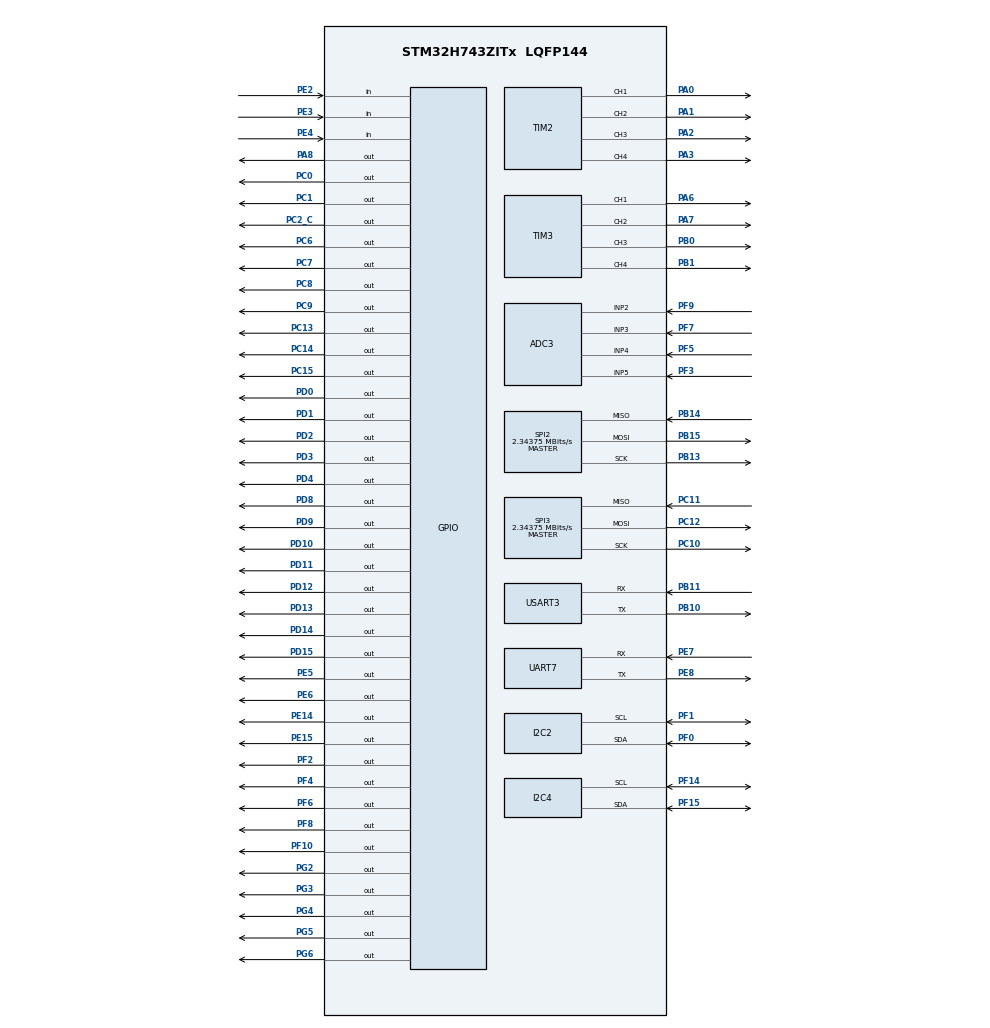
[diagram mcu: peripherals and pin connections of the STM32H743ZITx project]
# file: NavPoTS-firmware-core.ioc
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ADC3.Channel-0\#ChannelRegularConversion=ADC_CHANNEL_5
ADC3.NbrOfConversionFlag=1
ADC3.OffsetNumber-0\#ChannelRegularConversion=ADC_OFFSET_NONE
ADC3.OffsetSignedSaturation-0\#ChannelRegularConversion=DISABLE
ADC3.Rank-0\#ChannelRegularConversion=1
ADC3.SamplingTime-0\#ChannelRegularConversion=ADC_SAMPLETIME_1CYCLE_5
CORTEX_M7.default_mode_Activation=1
I2C2.Timing=0x307076AD
I2C4.Timing=0x307076AD
Mcu.Family=STM32H7
Mcu.Name=STM32H743ZITx
Mcu.Package=LQFP144
NVIC.PriorityGroup=NVIC_PRIORITYGROUP_4
PA0.Signal=S_TIM2_CH1_ETR
PA1.Signal=S_TIM2_CH2
PA11.Signal=USB_OTG_FS_DM
PA12.Signal=USB_OTG_FS_DP
PA13\ (JTMS/SWDIO).Signal=DEBUG_JTMS-SWDIO
PA14\ (JTCK/SWCLK).Signal=DEBUG_JTCK-SWCLK
PA2.Signal=S_TIM2_CH3
PA3.Signal=S_TIM2_CH4
PA6.Signal=S_TIM3_CH1
PA7.Signal=S_TIM3_CH2
PA8.Signal=GPIO_Output
PA9.Signal=USB_OTG_FS_VBUS
PB0.Signal=S_TIM3_CH3
PB1.Signal=S_TIM3_CH4
PB10.Mode=Asynchronous
PB10.Signal=USART3_TX
PB11.Mode=Asynchronous
PB11.Signal=USART3_RX
PB13.Mode=Full_Duplex_Master
PB13.Signal=SPI2_SCK
PB14.Mode=Full_Duplex_Master
PB14.Signal=SPI2_MISO
PB15.Mode=Full_Duplex_Master
PB15.Signal=SPI2_MOSI
PB3\ (JTDO/TRACESWO).Signal=DEBUG_JTDO-SWO
PC0.Signal=GPIO_Output
PC1.Signal=GPIO_Output
PC10.Mode=Full_Duplex_Master
PC10.Signal=SPI3_SCK
PC11.Mode=Full_Duplex_Master
PC11.Signal=SPI3_MISO
PC12.Mode=Full_Duplex_Master
PC12.Signal=SPI3_MOSI
PC13.Signal=GPIO_Output
PC14-OSC32_IN\ (OSC32_IN).Signal=GPIO_Output
PC15-OSC32_OUT\ (OSC32_OUT).Signal=GPIO_Output
PC2_C.Signal=GPIO_Output
PC6.Signal=GPIO_Output
PC7.Signal=GPIO_Output
PC8.Signal=GPIO_Output
PC9.Signal=GPIO_Output
PD0.Signal=GPIO_Output
PD1.Signal=GPIO_Output
PD10.Signal=GPIO_Output
PD11.Signal=GPIO_Output
PD12.Signal=GPIO_Output
PD13.Signal=GPIO_Output
PD14.Signal=GPIO_Output
PD15.Signal=GPIO_Output
PD2.Signal=GPIO_Output
PD3.Signal=GPIO_Output
PD4.Signal=GPIO_Output
PD8.Signal=GPIO_Output
PD9.Signal=GPIO_Output
PE14.Signal=GPIO_Output
PE15.Signal=GPIO_Output
PE2.Signal=GPIO_Input
PE3.Signal=GPIO_Input
PE4.Signal=GPIO_Input
PE5.Signal=GPIO_Output
PE6.Signal=GPIO_Output
PE7.Mode=Asynchronous
PE7.Signal=UART7_RX
PE8.Mode=Asynchronous
PE8.Signal=UART7_TX
PF0.Mode=I2C
PF0.Signal=I2C2_SDA
PF1.Mode=I2C
PF1.Signal=I2C2_SCL
PF10.Signal=GPIO_Output
PF14.Mode=I2C
PF14.Signal=I2C4_SCL
PF15.Mode=I2C
PF15.Signal=I2C4_SDA
PF2.Signal=GPIO_Output
PF3.Mode=IN5-Single-Ended
PF3.Signal=ADC3_INP5
PF4.Signal=GPIO_Output
PF5.Mode=IN4-Single-Ended
PF5.Signal=ADC3_INP4
PF6.Signal=GPIO_Output
PF7.Mode=IN3-Single-Ended
PF7.Signal=ADC3_INP3
PF8.Signal=GPIO_Output
PF9.Mode=IN2-Single-Ended
PF9.Signal=ADC3_INP2
PG2.Signal=GPIO_Output
PG3.Signal=GPIO_Output
PG4.Signal=GPIO_Output
PG5.Signal=GPIO_Output
PG6.Signal=GPIO_Output
PH0-OSC_IN\ (PH0).Mode=HSE-External-Clock-Source
PH0-OSC_IN\ (PH0).Signal=RCC_OSC_IN
ProjectManager.HeapSize=0x200
ProjectManager.StackSize=0x400
ProjectManager.TargetToolchain=STM32CubeIDE
RCC.ADCFreq_Value=75000000
RCC.APB1Freq_Value=118750000
RCC.APB2Freq_Value=118750000
RCC.APB3Freq_Value=118750000
RCC.APB4Freq_Value=118750000
RCC.CortexFreq_Value=475000000
RCC.D1PPRE=RCC_APB3_DIV2
RCC.D2PPRE1=RCC_APB1_DIV2
RCC.D2PPRE2=RCC_APB2_DIV2
RCC.D3PPRE=RCC_APB4_DIV2
RCC.DIVM1=2
RCC.DIVM2=2
RCC.DIVN1=76
RCC.DIVN2=12
RCC.EnbaleCSS=true
RCC.HCLKFreq_Value=237500000
RCC.HPRE=RCC_HCLK_DIV2
RCC.PLL2FRACN=0
RCC.PLLFRACN=0
RCC.PLLSourceVirtual=RCC_PLLSOURCE_HSE
RCC.SPI123CLockSelection=RCC_SPI123CLKSOURCE_PLL2
RCC.SYSCLKFreq_VALUE=475000000
RCC.SYSCLKSource=RCC_SYSCLKSOURCE_PLLCLK
RCC.USBFreq_Value=475000000
SH.S_TIM2_CH1_ETR.0=TIM2_CH1,PWM Generation1 CH1
SH.S_TIM2_CH2.0=TIM2_CH2,PWM Generation2 CH2
SH.S_TIM2_CH3.0=TIM2_CH3,PWM Generation3 CH3
SH.S_TIM2_CH4.0=TIM2_CH4,Output Compare4 CH4
SH.S_TIM3_CH1.0=TIM3_CH1,PWM Generation1 CH1
SH.S_TIM3_CH2.0=TIM3_CH2,PWM Generation2 CH2
SH.S_TIM3_CH3.0=TIM3_CH3,PWM Generation3 CH3
SH.S_TIM3_CH4.0=TIM3_CH4,PWM Generation4 CH4
SPI2.BaudRatePrescaler=SPI_BAUDRATEPRESCALER_32
SPI2.CalculateBaudRate=2.34375 MBits/s
SPI2.DataSize=SPI_DATASIZE_8BIT
SPI2.Direction=SPI_DIRECTION_2LINES
SPI2.Mode=SPI_MODE_MASTER
SPI2.VirtualType=VM_MASTER
SPI3.BaudRatePrescaler=SPI_BAUDRATEPRESCALER_32
SPI3.CalculateBaudRate=2.34375 MBits/s
SPI3.DataSize=SPI_DATASIZE_8BIT
SPI3.Direction=SPI_DIRECTION_2LINES
SPI3.Mode=SPI_MODE_MASTER
SPI3.VirtualType=VM_MASTER
TIM2.Channel-Output\ Compare4\ CH4=TIM_CHANNEL_4
TIM2.Channel-PWM\ Generation1\ CH1=TIM_CHANNEL_1
TIM2.Channel-PWM\ Generation2\ CH2=TIM_CHANNEL_2
TIM2.Channel-PWM\ Generation3\ CH3=TIM_CHANNEL_3
TIM3.Channel-PWM\ Generation1\ CH1=TIM_CHANNEL_1
TIM3.Channel-PWM\ Generation2\ CH2=TIM_CHANNEL_2
TIM3.Channel-PWM\ Generation3\ CH3=TIM_CHANNEL_3
TIM3.Channel-PWM\ Generation4\ CH4=TIM_CHANNEL_4
USART3.VirtualMode-Asynchronous=VM_ASYNC
VP_MEMORYMAP_VS_MEMORYMAP.Mode=CurAppReg
board=custom

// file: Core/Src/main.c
/* USER CODE BEGIN Header */
/**
  ******************************************************************************
  * @file           : main.c
  * @brief          : Main program body
  ******************************************************************************
  * @attention
  *
  * Copyright (c) 2026 STMicroelectronics.
  * All rights reserved.
  *
  * This software is licensed under terms that can be found in the LICENSE file
  * in the root directory of this software component.
  * If no LICENSE file comes with this software, it is provided AS-IS.
  *
  ******************************************************************************
  */
/* USER CODE END Header */
#include "main.h"
#include "adc.h"
#include "i2c.h"
#include "spi.h"
#include "tim.h"
#include "usart.h"
#include "gpio.h"

/* USER CODE BEGIN Includes */
#include <stdio.h>
#include "ASM330LHHXTR.h"
#include "H3LIS331DL.h"
#include "MMC5983MA.h"
/* USER CODE END Includes */

void SystemClock_Config(void);
void PeriphCommonClock_Config(void);
static void MPU_Config(void);

int main(void)
{

  /* MPU Configuration--------------------------------------------------------*/
  MPU_Config();

  /* MCU Configuration--------------------------------------------------------*/

  /* Reset of all peripherals, Initializes the Flash interface and the Systick. */
  HAL_Init();

  /* Configure the system clock */
  SystemClock_Config();

  /* Configure the peripherals common clocks */
  PeriphCommonClock_Config();

  /* Initialize all configured peripherals */
  MX_GPIO_Init();
  MX_SPI3_Init();
  MX_SPI2_Init();
  MX_UART7_Init();
  MX_USART3_UART_Init();
  MX_ADC3_Init();
  MX_I2C2_Init();
  MX_I2C4_Init();
  MX_TIM2_Init();
  MX_TIM3_Init();
  /* USER CODE BEGIN 2 */
  ASM330LHHXTR_Data data;

  ASM330LHHXTR_Verify();
  ASM330LHHXTR_Init();
  H3LIS331DL_Verify();
  MMC5983MA_Verify();

  /* USER CODE END 2 */

  /* Infinite loop */
  while (1)
  {

    /* USER CODE BEGIN 3 */
	ASM330LHHXTR_ReadData(&data);
	printf("temp %f, gx %f, gy %f, gz %f, ax %f, ay %f, az %f\r\n", data.temp, data.gx, data.gy, data.gz, data.ax, data.ay, data.az);
	HAL_Delay(150);
  }
  /* USER CODE END 3 */
}

void SystemClock_Config(void)
{
  RCC_OscInitTypeDef RCC_OscInitStruct = {0};
  RCC_ClkInitTypeDef RCC_ClkInitStruct = {0};

  /** Supply configuration update enable
  */
  HAL_PWREx_ConfigSupply(PWR_LDO_SUPPLY);

  /** Configure the main internal regulator output voltage
  */
  __HAL_PWR_VOLTAGESCALING_CONFIG(PWR_REGULATOR_VOLTAGE_SCALE0);

  while(!__HAL_PWR_GET_FLAG(PWR_FLAG_VOSRDY)) {}

  /** Initializes the RCC Oscillators according to the specified parameters
  * in the RCC_OscInitTypeDef structure.
  */
  RCC_OscInitStruct.OscillatorType = RCC_OSCILLATORTYPE_HSE;
  RCC_OscInitStruct.HSEState = RCC_HSE_BYPASS;
  RCC_OscInitStruct.PLL.PLLState = RCC_PLL_ON;
  RCC_OscInitStruct.PLL.PLLSource = RCC_PLLSOURCE_HSE;
  RCC_OscInitStruct.PLL.PLLM = 2;
  RCC_OscInitStruct.PLL.PLLN = 76;
  RCC_OscInitStruct.PLL.PLLP = 2;
  RCC_OscInitStruct.PLL.PLLQ = 2;
  RCC_OscInitStruct.PLL.PLLR = 2;
  RCC_OscInitStruct.PLL.PLLRGE = RCC_PLL1VCIRANGE_3;
  RCC_OscInitStruct.PLL.PLLVCOSEL = RCC_PLL1VCOWIDE;
  RCC_OscInitStruct.PLL.PLLFRACN = 0;
  if (HAL_RCC_OscConfig(&RCC_OscInitStruct) != HAL_OK)
  {
    Error_Handler();
  }

  /** Initializes the CPU, AHB and APB buses clocks
  */
  RCC_ClkInitStruct.ClockType = RCC_CLOCKTYPE_HCLK|RCC_CLOCKTYPE_SYSCLK
                              |RCC_CLOCKTYPE_PCLK1|RCC_CLOCKTYPE_PCLK2
                              |RCC_CLOCKTYPE_D3PCLK1|RCC_CLOCKTYPE_D1PCLK1;
  RCC_ClkInitStruct.SYSCLKSource = RCC_SYSCLKSOURCE_PLLCLK;
  RCC_ClkInitStruct.SYSCLKDivider = RCC_SYSCLK_DIV1;
  RCC_ClkInitStruct.AHBCLKDivider = RCC_HCLK_DIV2;
  RCC_ClkInitStruct.APB3CLKDivider = RCC_APB3_DIV2;
  RCC_ClkInitStruct.APB1CLKDivider = RCC_APB1_DIV2;
  RCC_ClkInitStruct.APB2CLKDivider = RCC_APB2_DIV2;
  RCC_ClkInitStruct.APB4CLKDivider = RCC_APB4_DIV2;

  if (HAL_RCC_ClockConfig(&RCC_ClkInitStruct, FLASH_LATENCY_4) != HAL_OK)
  {
    Error_Handler();
  }

  /** Enables the Clock Security System
  */
  HAL_RCC_EnableCSS();
}

void PeriphCommonClock_Config(void)
{
  RCC_PeriphCLKInitTypeDef PeriphClkInitStruct = {0};

  /** Initializes the peripherals clock
  */
  PeriphClkInitStruct.PeriphClockSelection = RCC_PERIPHCLK_ADC|RCC_PERIPHCLK_SPI3
                              |RCC_PERIPHCLK_SPI2;
  PeriphClkInitStruct.PLL2.PLL2M = 2;
  PeriphClkInitStruct.PLL2.PLL2N = 12;
  PeriphClkInitStruct.PLL2.PLL2P = 2;
  PeriphClkInitStruct.PLL2.PLL2Q = 2;
  PeriphClkInitStruct.PLL2.PLL2R = 2;
  PeriphClkInitStruct.PLL2.PLL2RGE = RCC_PLL2VCIRANGE_3;
  PeriphClkInitStruct.PLL2.PLL2VCOSEL = RCC_PLL2VCOMEDIUM;
  PeriphClkInitStruct.PLL2.PLL2FRACN = 0;
  PeriphClkInitStruct.Spi123ClockSelection = RCC_SPI123CLKSOURCE_PLL2;
  PeriphClkInitStruct.AdcClockSelection = RCC_ADCCLKSOURCE_PLL2;
  if (HAL_RCCEx_PeriphCLKConfig(&PeriphClkInitStruct) != HAL_OK)
  {
    Error_Handler();
  }
}

/* USER CODE BEGIN 4 */
void HAL_RCC_CSSCallback(void)
{
	//printf("CSS Callback Triggered!");
	HAL_GPIO_WritePin(GPIOE, GPIO_PIN_14, GPIO_PIN_SET);
	while(1)
	{

	}
}

int _write(int file, char *ptr, int len)
{
  HAL_UART_Transmit(&huart7, (uint8_t *)ptr, len, HAL_MAX_DELAY);
  return len;
}
/* USER CODE END 4 */

 /* MPU Configuration */

void MPU_Config(void)
{
  MPU_Region_InitTypeDef MPU_InitStruct = {0};

  /* Disables the MPU */
  HAL_MPU_Disable();

  /** Initializes and configures the Region and the memory to be protected
  */
  MPU_InitStruct.Enable = MPU_REGION_ENABLE;
  MPU_InitStruct.Number = MPU_REGION_NUMBER0;
  MPU_InitStruct.BaseAddress = 0x0;
  MPU_InitStruct.Size = MPU_REGION_SIZE_4GB;
  MPU_InitStruct.SubRegionDisable = 0x87;
  MPU_InitStruct.TypeExtField = MPU_TEX_LEVEL0;
  MPU_InitStruct.AccessPermission = MPU_REGION_NO_ACCESS;
  MPU_InitStruct.DisableExec = MPU_INSTRUCTION_ACCESS_DISABLE;
  MPU_InitStruct.IsShareable = MPU_ACCESS_SHAREABLE;
  MPU_InitStruct.IsCacheable = MPU_ACCESS_NOT_CACHEABLE;
  MPU_InitStruct.IsBufferable = MPU_ACCESS_NOT_BUFFERABLE;

  HAL_MPU_ConfigRegion(&MPU_InitStruct);
  /* Enables the MPU */
  HAL_MPU_Enable(MPU_PRIVILEGED_DEFAULT);

}

void Error_Handler(void)
{
  __disable_irq();
  while (1)
  {
  }
}
